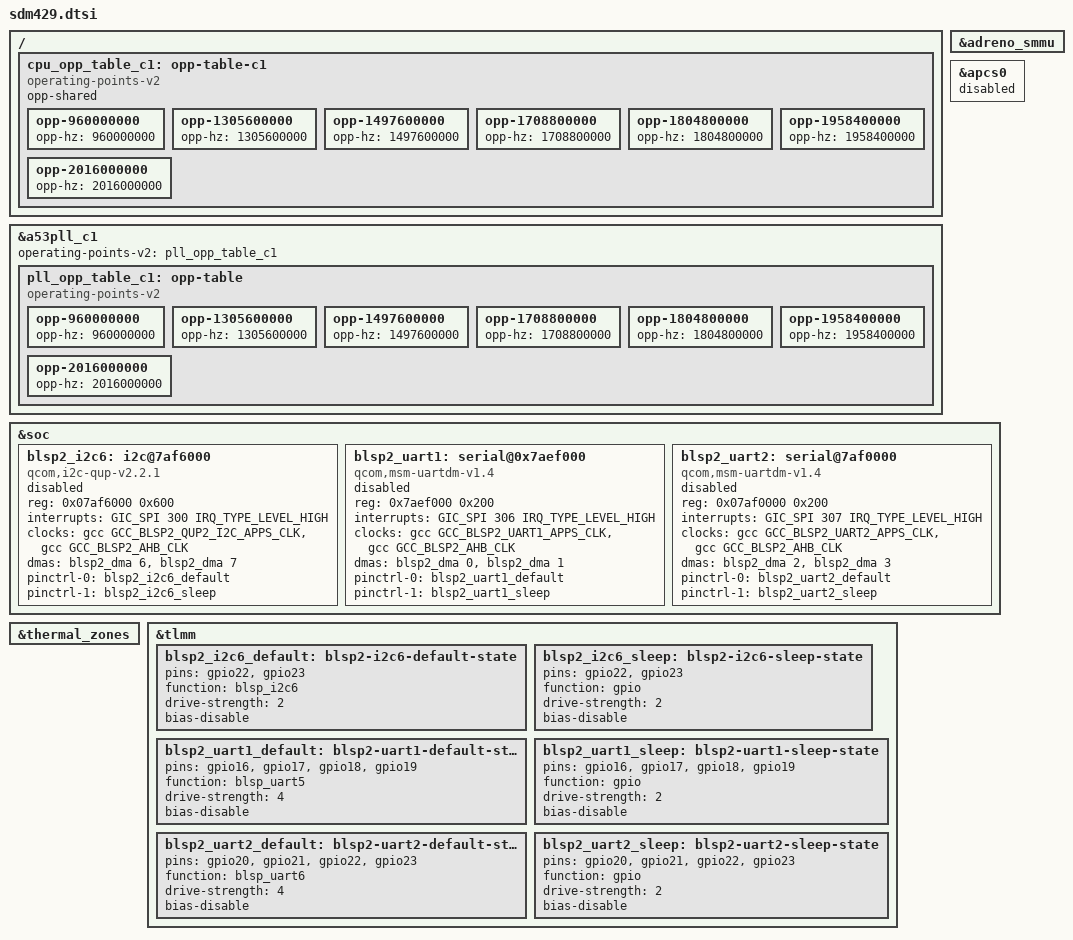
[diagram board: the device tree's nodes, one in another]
// SPDX-License-Identifier: BSD-3-Clause
/*
 * Copyright (c) 2025, Simon Sommer <misom@symlinks.dev>
 */
#include "sdm439.dtsi"

/delete-node/ &pll_opp_table_c1;
/delete-node/ &cpu_opp_table_c1;

/ {
	cpu_opp_table_c1: opp-table-c1 {
		compatible = "operating-points-v2";
		opp-shared;

		opp-960000000 {
			opp-hz = /bits/ 64 <960000000>;
		};

		opp-1305600000 {
			opp-hz = /bits/ 64 <1305600000>;
		};

		opp-1497600000 {
			opp-hz = /bits/ 64 <1497600000>;
		};

		opp-1708800000 {
			opp-hz = /bits/ 64 <1708800000>;
		};

		opp-1804800000 {
			opp-hz = /bits/ 64 <1804800000>;
		};

		opp-1958400000 {
			opp-hz = /bits/ 64 <1958400000>;
		};

		opp-2016000000 {
			opp-hz = /bits/ 64 <2016000000>;
		};
	};
};

&a53pll_c1 {
	operating-points-v2 = <&pll_opp_table_c1>;
	pll_opp_table_c1: opp-table {
		compatible = "operating-points-v2";

		opp-960000000 {
			opp-hz = /bits/ 64 <960000000>;
		};

		opp-1305600000 {
			opp-hz = /bits/ 64 <1305600000>;
		};

		opp-1497600000 {
			opp-hz = /bits/ 64 <1497600000>;
		};

		opp-1708800000 {
			opp-hz = /bits/ 64 <1708800000>;
		};

		opp-1804800000 {
			opp-hz = /bits/ 64 <1804800000>;
		};

		opp-1958400000 {
			opp-hz = /bits/ 64 <1958400000>;
		};

		opp-2016000000 {
			opp-hz = /bits/ 64 <2016000000>;
		};
	};
};

&adreno_smmu {
	/delete-node/ iommu-ctx@2000; // gfx3d_secure
};

&apcs0 {
	status = "disabled";
};

&soc {
	blsp2_i2c6: i2c@7af6000 {
		compatible = "qcom,i2c-qup-v2.2.1";
		reg = <0x07af6000 0x600>;
		interrupts = <GIC_SPI 300 IRQ_TYPE_LEVEL_HIGH>;
		clock-names = "core", "iface";
		clocks = <&gcc GCC_BLSP2_QUP2_I2C_APPS_CLK>,
			 <&gcc GCC_BLSP2_AHB_CLK>;
		dmas = <&blsp2_dma 6>, <&blsp2_dma 7>;
		dma-names = "tx", "rx";

		pinctrl-names = "default", "sleep";
		pinctrl-0 = <&blsp2_i2c6_default>;
		pinctrl-1 = <&blsp2_i2c6_sleep>;

		#address-cells = <1>;
		#size-cells = <0>;

		status = "disabled";
	};

	blsp2_uart1: serial@0x7aef000 {
		compatible = "qcom,msm-uartdm-v1.4", "qcom,msm-uartdm";
		reg = <0x7aef000 0x200>;
		interrupts = <GIC_SPI 306 IRQ_TYPE_LEVEL_HIGH>;
		clocks = <&gcc GCC_BLSP2_UART1_APPS_CLK>, <&gcc GCC_BLSP2_AHB_CLK>;
		clock-names = "core", "iface";
		dmas = <&blsp2_dma 0>, <&blsp2_dma 1>;
		dma-names = "tx", "rx";

		pinctrl-names = "default", "sleep";
		pinctrl-0 = <&blsp2_uart1_default>;
		pinctrl-1 = <&blsp2_uart1_sleep>;

		status = "disabled";
	};

	blsp2_uart2: serial@7af0000 {
		compatible = "qcom,msm-uartdm-v1.4", "qcom,msm-uartdm";
		reg = <0x07af0000 0x200>;

		interrupts = <GIC_SPI 307 IRQ_TYPE_LEVEL_HIGH>;

		clocks = <&gcc GCC_BLSP2_UART2_APPS_CLK>, <&gcc GCC_BLSP2_AHB_CLK>;
		clock-names = "core", "iface";

		dmas = <&blsp2_dma 2>, <&blsp2_dma 3>;
		dma-names = "tx", "rx";

		pinctrl-names = "default", "sleep";
		pinctrl-0 = <&blsp2_uart2_default>;
		pinctrl-1 = <&blsp2_uart2_sleep>;

		status = "disabled";
	};
};

&thermal_zones {
	/delete-node/ cpuss0-thermal;
};

&tlmm {
	blsp2_i2c6_default: blsp2-i2c6-default-state {
		pins = "gpio22", "gpio23";
		function = "blsp_i2c6";
		drive-strength = <2>;
		bias-disable;
	};

	blsp2_i2c6_sleep: blsp2-i2c6-sleep-state {
		pins = "gpio22", "gpio23";
		function = "gpio";
		drive-strength = <2>;
		bias-disable;
	};

	blsp2_uart1_default: blsp2-uart1-default-state {
		pins = "gpio16", "gpio17", "gpio18", "gpio19";
		function = "blsp_uart5";
		drive-strength = <4>;
		bias-disable;
	};

	blsp2_uart1_sleep: blsp2-uart1-sleep-state {
		pins = "gpio16", "gpio17", "gpio18", "gpio19";
		function = "gpio";
		drive-strength = <2>;
		bias-disable;
	};

	blsp2_uart2_default: blsp2-uart2-default-state {
		pins = "gpio20", "gpio21", "gpio22", "gpio23";
		function = "blsp_uart6";
		drive-strength = <4>;
		bias-disable;
	};

	blsp2_uart2_sleep: blsp2-uart2-sleep-state {
		pins = "gpio20", "gpio21", "gpio22", "gpio23";
		function = "gpio";
		drive-strength = <2>;
		bias-disable;
	};
};
